AUTOSAR XML (schema 00053)
package /ComponentTypes
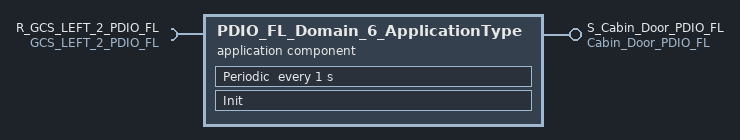
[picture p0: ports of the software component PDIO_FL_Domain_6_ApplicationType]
  application sw component type PDIO_FL_Domain_6_ApplicationType
    provide port S_Cabin_Door_PDIO_FL: nonqueued-sender-com-spec{data-element=Cabin_Door_PDIO_FL_t, init-value=fields=ElementConstant:0}, provided-interface=Cabin_Door_PDIO_FL
    require port R_GCS_LEFT_2_PDIO_FL: nonqueued-receiver-com-spec{data-element=GCS_LEFT_2_PDIO_FL_t, init-value=fields=ElementConstant:0}, required-interface=GCS_LEFT_2_PDIO_FL
    behavior PDIO_FL_Domain_6_ApplicationType_InternalBehavior: handle-termination-and-restart=NO-SUPPORT
      init event InitEvent: start-on-event=Init
      timing event TMT_Runnable: start-on-event=Periodic, period=1
      runnable Init
      runnable Periodic
        data-receive-point-by-arguments:
          access REC_R_GCS_LEFT_2_PDIO_FL_GCS_LEFT_2_PDIO_FL_t: accessed-variable=R_GCS_LEFT_2_PDIO_FL.GCS_LEFT_2_PDIO_FL_t
        data-send-points:
          access SEND_S_Cabin_Door_PDIO_FL_Cabin_Door_PDIO_FL_t: accessed-variable=S_Cabin_Door_PDIO_FL.Cabin_Door_PDIO_FL_t
    symbol props PDIO_FL_Domain_6_Application
  swc implementation PDIO_FL_Domain_6_ApplicationType_Implementation: behavior=PDIO_FL_Domain_6_ApplicationType_InternalBehavior
    code-descriptors:
      code Default: artifact-descriptors=autosar-engineering-object={short-label=Default, category=SWSRC}
